# MK70F12 register map
Vendor: Freescale Semiconductor, Inc.; Series: Kinetis_K; File version: 1.6
CPU: CM4 r0p1, little endian, no MPU, FPU, VTOR, 4 interrupt priority bits
Registers are 32-bit, read-write, reset 0x0 unless marked. A register's access mark holds for its fields unless they carry their own. Offsets are from the block's base; [hi:lo] are bit positions; {n}, {i} and the like mark numbered series; 'fields as' and 'values as' point back to an identical list.

## DMAMUX0 — DMA channel multiplexor
Base 0x40021000; register names take the prefix DMAMUX0_
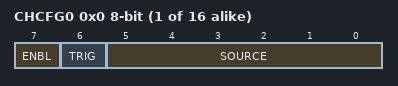
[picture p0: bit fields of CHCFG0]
{0x0+i} CHCFG{i} (i=0..15) 8-bit — Channel Configuration Register
  [7] ENBL — DMA Channel Enable
    0=DMA channel is disabled. This mode is primarily used during configuration of the DMA Mux. The DMA has separate channel enables/disables, which should be used to disable or re-configure a DMA channel.; 1=DMA channel is enabled
  [6] TRIG — DMA Channel Trigger Enable
    0=Triggering is disabled. If triggering is disabled, and the ENBL bit is set, the DMA Channel will simply route the specified source to the DMA channel. (normal mode); 1=Triggering is enabled. If triggering is enabled, and the ENBL bit is set, the DMAMUX is in periodic trigger mode.
  [5:0] SOURCE — DMA Channel Source (slot)
    0=Disable_Signal; 2=UART0_Rx_Signal; 3=UART0_Tx_Signal; 4=UART1_Rx_Signal; 5=UART1_Tx_Signal; 6=UART2_Rx_Signal; 7=UART2_Tx_Signal; 8=UART3_Rx_Signal; 9=UART3_Tx_Signal; 10=UART4_Rx_Signal; 11=UART4_Tx_Signal; 12=UART5_Rx_Signal; 13=UART5_Tx_Signal; 14=I2S0_Rx_Signal; 15=I2S0_Tx_Signal; 16=SPI0_Rx_Signal; 17=SPI0_Tx_Signal; 18=SPI1_Rx_Signal; 19=SPI1_Tx_Signal; 20=SPI2_Rx_Signal; 21=SPI2_Tx_Signal; 22=I2C0_Signal; 23=I2C1_Signal; {v}=FTM0_Channel{v-24}_Signal (v=24..31); 32=FTM1_Channel0_Signal; 33=FTM1_Channel1_Signal; 34=FTM2_Channel0_Signal; 35=FTM2_Channel1_Signal; 40=ADC0_Signal; 41=ADC1_Signal; 42=CMP0_Signal; 43=CMP1_Signal; 44=CMP2_Signal; 45=DAC0_Signal; 46=DAC1_Signal; 47=CMT_Signal; 48=PDB0_Signal; 49=PORTA_Signal; 50=PORTB_Signal; 51=PORTC_Signal; 52=PORTD_Signal; 53=PORTE_Signal

## DMAMUX1 — DMA channel multiplexor
Base 0x40022000; register names take the prefix DMAMUX1_
Registers as DMAMUX0.

## CRC — Cyclic Redundancy Check
Base 0x40032000; register names take the prefix CRC_
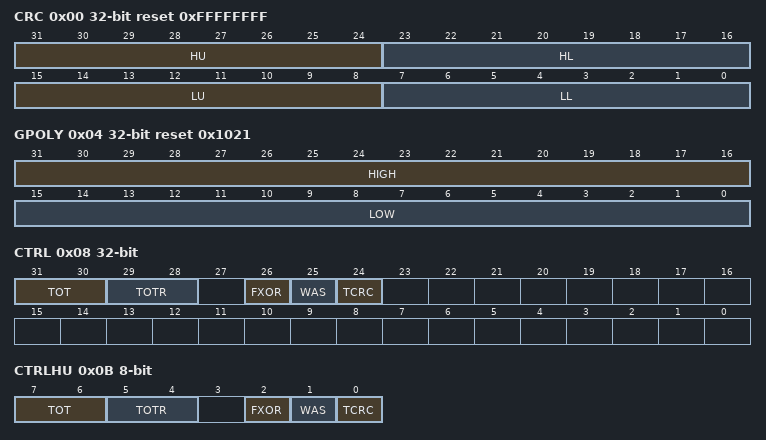
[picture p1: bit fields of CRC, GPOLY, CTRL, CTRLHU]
0x00 CRC reset 0xFFFFFFFF (CRC view) — CRC Data Register
  [31:24] HU — CRC High Upper Byte
  [23:16] HL — CRC High Lower Byte
  [15:8] LU — CRC Low Upper Byte
  [7:0] LL — CRC Low Lower Byte
0x00 CRCL 16-bit reset 0xFFFF (CRC view) — CRC_CRCL register.
  [15:0] CRCL — CRCL stores the lower 16 bits of the 16/32 bit CRC
0x00 CRCLL 8-bit reset 0xFF (CRC view) — CRC_CRCLL register.
  [7:0] CRCLL — CRCLL stores the first 8 bits of the 32 bit CRC
0x01 CRCLU 8-bit reset 0xFF — CRC_CRCLU register.
  [7:0] CRCLU — CRCLL stores the second 8 bits of the 32 bit CRC
0x02 CRCH 16-bit reset 0xFFFF (CRC view) — CRC_CRCH register.
  [15:0] CRCH — CRCH stores the high 16 bits of the 16/32 bit CRC
0x02 CRCHL 8-bit reset 0xFF (CRC view) — CRC_CRCHL register.
  [7:0] CRCHL — CRCHL stores the third 8 bits of the 32 bit CRC
0x03 CRCHU 8-bit reset 0xFF — CRC_CRCHU register.
  [7:0] CRCHU — CRCHU stores the fourth 8 bits of the 32 bit CRC
0x04 GPOLY reset 0x1021 (CRC view) — CRC Polynomial Register
  [31:16] HIGH — High polynominal half-word
  [15:0] LOW — Low polynominal half-word
0x04 GPOLYL 16-bit reset 0xFFFF (CRC view) — CRC_GPOLYL register.
  [15:0] GPOLYL — POLYL stores the lower 16 bits of the 16/32 bit CRC polynomial value
0x04 GPOLYLL 8-bit reset 0xFF (CRC view) — CRC_GPOLYLL register.
  [7:0] GPOLYLL — POLYLL stores the first 8 bits of the 32 bit CRC
0x05 GPOLYLU 8-bit reset 0xFF — CRC_GPOLYLU register.
  [7:0] GPOLYLU — POLYLL stores the second 8 bits of the 32 bit CRC
0x06 GPOLYH 16-bit reset 0xFFFF (CRC view) — CRC_GPOLYH register.
  [15:0] GPOLYH — POLYH stores the high 16 bits of the 16/32 bit CRC polynomial value
0x06 GPOLYHL 8-bit reset 0xFF (CRC view) — CRC_GPOLYHL register.
  [7:0] GPOLYHL — POLYHL stores the third 8 bits of the 32 bit CRC
0x07 GPOLYHU 8-bit reset 0xFF — CRC_GPOLYHU register.
  [7:0] GPOLYHU — POLYHU stores the fourth 8 bits of the 32 bit CRC
0x08 CTRL — CRC Control Register
  [31:30] TOT — Type of Transpose for Writes
    0=No transposition; 1=Bits in bytes are transposed; bytes are not transposed; 2=Both bits in bytes and bytes are transposed; 3=Only bytes are transposed; no bits in a byte are transposed
  [29:28] TOTR — Type of Transpose for Read
    values as TOT
  [26] FXOR — Complement Read of CRC data register
    0=No XOR on reading; 1=Invert or complement the read value of the CRC data register
  [25] WAS — Write CRC data register as seed
    0=Writes to the CRC data register are data values; 1=Writes to the CRC data register are seed values
  [24] TCRC — Width of CRC protocol.
    0=16-bit CRC protocol; 1=32-bit CRC protocol
0x0B CTRLHU 8-bit — CRC_CTRLHU register.
  [7:6] TOT
    0=No Transposition; 1=Bits in bytes are transposed, bytes are not transposed; 2=Both bits in bytes and bytes are transposed; 3=Only bytes are transposed; no bits in a byte are transposed
  [5:4] TOTR
    values as TOT
  [2] FXOR
    0=No XOR on reading; 1=Invert or complement the read value of CRC data register
  [1] WAS
    0=Writes to CRC data register are data values; 1=Writes to CRC data reguster are seed values
  [0] TCRC
    0=16-bit CRC protocol; 1=32-bit CRC protocol
